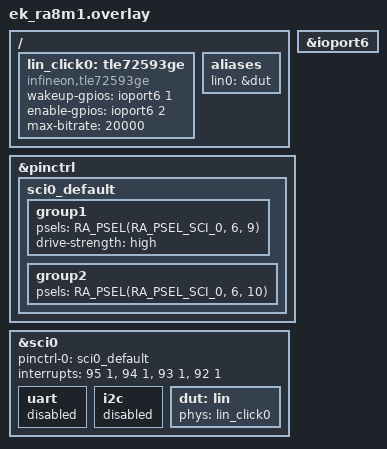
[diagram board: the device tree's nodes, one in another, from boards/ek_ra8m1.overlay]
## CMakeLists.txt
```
# SPDX-License-Identifier: Apache-2.0

cmake_minimum_required(VERSION 3.20.0)
find_package(Zephyr REQUIRED HINTS $ENV{ZEPHYR_BASE})
project(lin_ncv7430)

file(GLOB app_sources src/*.c)
target_sources(app PRIVATE ${app_sources})
```

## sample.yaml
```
sample:
  name: LIN driver NCV7430 sample
tests:
  sample.drivers.lin.ncv7430:
    tags: lin
    depends_on: lin
    integration_platforms:
      - ek_ra8m1/r7fa8m1ahecbd
    harness: console
    harness_config:
      type: one_line
      regex:
        - "NCV7430 sample started"
    extra_args:
      - platform:ek_ra8m1/r7fa8m1ahecbd:SHIELD=mikroe_lin_click
```

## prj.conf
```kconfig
CONFIG_LIN=y
```

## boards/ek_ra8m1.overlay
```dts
/*
 * Copyright (c) 2025 Renesas Electronics Corporation
 *
 * SPDX-License-Identifier: Apache-2.0
 */

/ {
	lin_click0: tle72593ge {
		compatible = "infineon,tle72593ge", "lin-transceiver-gpio";
		wakeup-gpios = <&ioport6 1 GPIO_ACTIVE_HIGH>;
		enable-gpios = <&ioport6 2 GPIO_ACTIVE_HIGH>;
		max-bitrate = <20000>;
		#phy-cells = <0>;
	};

	aliases {
		lin0 = &dut;
	};
};

&ioport6 {
	status = "okay";
};

&pinctrl {
	sci0_default: sci0_default {
		group1 {
			/* TXD */
			psels = <RA_PSEL(RA_PSEL_SCI_0, 6, 9)>;
			drive-strength = "high";
		};

		group2 {
			/* RXD */
			psels = <RA_PSEL(RA_PSEL_SCI_0, 6, 10)>;
		};
	};
};

&sci0 {
	pinctrl-0 = <&sci0_default>;
	pinctrl-names = "default";
	interrupts = <95 1>, <94 1>, <93 1>, <92 1>;
	interrupt-names = "rxi", "txi", "tei", "eri";
	status = "okay";

	uart {
		status = "disabled";
	};

	i2c {
		status = "disabled";
	};

	dut: lin {
		phys = <&lin_click0>;
		status = "okay";
	};
};
```

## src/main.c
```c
/*
 * Copyright (c) 2025 Renesas Electronics Corporation
 *
 * SPDX-License-Identifier: Apache-2.0
 */

#include <zephyr/kernel.h>
#include <zephyr/sys/printk.h>
#include <zephyr/device.h>
#include <zephyr/drivers/lin.h>
#include <zephyr/sys/byteorder.h>

#include "ncv7430.h"

#define LIN_BUS_BAUDRATE            19200U
#define LIN_BUS_BREAK_LEN           13U
#define LIN_BUS_BREAK_DELIMITER_LEN 1U

#define LED_CHANGE_INTERVAL_MS 1000

/* RGB LED test sequence (RGB888 format, separate channels) */
static const struct rgb_led_color rgb_led_test_colors[8] = {
	{255, 0, 0},   {0, 255, 0},   {0, 0, 255},     {255, 255, 0},
	{0, 255, 255}, {255, 0, 255}, {255, 255, 255}, {0, 0, 0},
};

/* RGB LED color names in string */
static const unsigned char rgb_test_color_name[][8] = {
	"Red", "Green", "Blue", "Yellow", "Cyan", "Magenta", "White", "Black",
};

static const struct lin_config dut_config = {
	.mode = LIN_MODE_COMMANDER,
	.baudrate = LIN_BUS_BAUDRATE,
	.break_len = LIN_BUS_BREAK_LEN,
	.break_delimiter_len = LIN_BUS_BREAK_DELIMITER_LEN,
	.flags = 0,
};

static unsigned int current_led_idx;

#if DT_HAS_ALIAS(lin0)
static const struct device *const dev = DEVICE_DT_GET(DT_ALIAS(lin0));
#else
#error "No LIN device found."
#endif

int main(void)
{
	int ret;

	ret = device_is_ready(dev);
	if (!ret) {
		printk("NCV7430 device not found\n");
		return 0;
	}

	ret = lin_configure(dev, &dut_config);
	if (ret) {
		printk("LIN configure failed: %d\n", ret);
		return 0;
	}

	ret = lin_start(dev);
	if (ret) {
		printk("LIN start failed: %d\n", ret);
		return 0;
	}

	ret = ncv7430_init(dev, NCV7430_NODE_ADDRESS);
	if (ret) {
		printk("NCV7430 initialization failed: %d\n", ret);
		return 0;
	}

	printk("NCV7430 sample started\n");
	current_led_idx = 0;

	while (true) {
		struct rgb_led_color color = rgb_led_test_colors[current_led_idx];
		struct rgb_led_color read_color;
		uint32_t color_code;

		ret = ncv7430_set_led_color(dev, NCV7430_NODE_ADDRESS, &color);
		if (ret != 0) {
			printk("Failed to set LED color: %d\n", ret);
			return 0;
		}

		ret = ncv7430_get_led_color(dev, NCV7430_NODE_ADDRESS, &read_color);
		if (ret != 0) {
			printk("Failed to get LED color: %d\n", ret);
			return 0;
		}

		color_code = sys_get_be24((uint8_t *)&read_color);
		printk("Set LED color: %s - read back actual color code: 0x%06X\n",
		       rgb_test_color_name[current_led_idx], color_code);

		if ((read_color.red != color.red) || (read_color.green != color.green) ||
		    (read_color.blue != color.blue)) {
			printk("Warning: Mismatch in set and read back color "
			       "values!\n");
		}

		current_led_idx++;
		if (current_led_idx == ARRAY_SIZE(rgb_led_test_colors)) {
			current_led_idx = 0;
		}

		k_msleep(LED_CHANGE_INTERVAL_MS);
	}

	return 0;
}
```

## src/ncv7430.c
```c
/*
 * Copyright (c) 2025 Renesas Electronics Corporation
 *
 * SPDX-License-Identifier: Apache-2.0
 */

#include <string.h>

#include <zephyr/kernel.h>
#include <zephyr/sys/printk.h>
#include <zephyr/drivers/lin.h>

#include "ncv7430.h"

static struct lin_msg ncv7430_msg;
static uint8_t tx_data[LIN_MAX_DLEN];
static uint8_t rx_data[LIN_MAX_DLEN];
static volatile bool tx_complete;
static volatile bool rx_complete;
static volatile uint32_t ncv7430_event_flags;

void ncv7430_event_handler(const struct device *dev, const struct lin_event *event, void *user_data)
{
	ARG_UNUSED(dev);
	ARG_UNUSED(user_data);

	switch (event->type) {
	case LIN_EVT_TX_DATA:
		tx_complete = true;
		ncv7430_event_flags = event->status;
		break;
	case LIN_EVT_RX_DATA:
		rx_complete = true;
		ncv7430_event_flags = event->status;
		break;
	case LIN_EVT_ERR:
		printk("NCV7430 LIN error event: 0x%08X\n", event->error_flags);
		ncv7430_event_flags = -EIO;
		break;
	default:
		break;
	}
}

static int ncv7430_send_command(const struct device *dev, const uint8_t cmd_id, const uint8_t *data,
				const uint8_t data_len)
{
	int ret;

	tx_complete = false;
	ncv7430_event_flags = 0;

	ncv7430_msg.id = cmd_id;
	ncv7430_msg.data_len = data_len;
	ncv7430_msg.checksum_type = LIN_CHECKSUM_CLASSIC;
	ncv7430_msg.flags = 0;

	memcpy(ncv7430_msg.data, data, data_len);

	ret = lin_send(dev, &ncv7430_msg, K_FOREVER);
	if (ret) {
		printk("Failed to send NCV7430 command 0x%02X: %d\n", cmd_id, ret);
		return ret;
	}

	if (!WAIT_FOR(tx_complete, 500000, k_sleep(K_MSEC(10)))) {
		printk("Timeout waiting for NCV7430 command 0x%02X TX complete\n", cmd_id);
		return -EAGAIN;
	}

	return ncv7430_event_flags;
}

static int ncv7430_request_response(const struct device *dev, const uint8_t cmd_id, uint8_t *data,
				    const uint8_t data_len)
{
	int ret;

	rx_complete = false;
	ncv7430_event_flags = 0;

	ncv7430_msg.id = cmd_id;
	ncv7430_msg.data_len = data_len;
	ncv7430_msg.checksum_type = LIN_CHECKSUM_CLASSIC;
	ncv7430_msg.flags = 0;

	ret = lin_receive(dev, &ncv7430_msg, K_FOREVER);
	if (ret) {
		printk("Failed to receive NCV7430 response for command 0x%02X: %d\n", cmd_id, ret);
		return ret;
	}

	if (!WAIT_FOR(rx_complete, 500000, k_sleep(K_MSEC(10)))) {
		printk("Timeout waiting for NCV7430 response for command 0x%02X\n", cmd_id);
		return -EAGAIN;
	}

	memcpy(data, ncv7430_msg.data, data_len);

	return ncv7430_event_flags;
}

int ncv7430_init(const struct device *dev, uint8_t addr)
{
	uint8_t leds_en = (NCV7430_LED_R_EN_MSK | NCV7430_LED_G_EN_MSK | NCV7430_LED_B_EN_MSK);
	int ret;

	ret = lin_set_event_callback(dev, ncv7430_event_handler, NULL);
	if (ret) {
		printk("Failed to set NCV7430 event handler: %d\n", ret);
		return ret;
	}

	/*
	 * NCV7430 Set_LED_Control WRITING FRAME
	 * Frame ID: 0x23
	 * Data Length: 4 bytes
	 * Data:
	 *      Byte 0:
	 *              [7:7] Broad: Individual Addressing (1) or Group Addressing (0)
	 *              [6:6] Fixed as 1
	 *              [5:0] AD: NCV7430 Node Address - unused in case of Group Addressing
	 *              Other bits are filled as 0
	 *      Byte 1: 0xFF (FILL)
	 *      Byte 2: 0xFF (FILL)
	 *      Byte 3:
	 *              [0:0] Fixed as 1
	 *              [3:1] LEDs Enable: 0x07 (All LEDs On), 0x00 (All LEDs Off)
	 *              [5:5] Global LEDs Enable: 1 (Enabled), 0 (Disabled)
	 *              [6:6] LED Modulation Frequency: 0 (122 Hz), 1 (244 Hz)
	 *              Other bits are filled as 0
	 */
	tx_data[0] = (addr & 0x3F) | BIT(6) | BIT(7);
	tx_data[1] = NCV7430_FILL;
	tx_data[2] = NCV7430_FILL;
	tx_data[3] = BIT(0) | (leds_en << 1) | BIT(5) | NCV7430_LED_MOD_FREQ_122_HZ << 6;

	ret = ncv7430_send_command(dev, NCV7430_FRAME_ID_SET_LED_CONTROL_WRITING, tx_data,
				   NCV7430_4_BYTES);
	if (ret) {
		return ret;
	}

	return 0;
}

int ncv7430_set_led_color(const struct device *dev, uint8_t addr, struct rgb_led_color *color)
{
	/**
	 * NCV7430 Set_Color WRITING FRAME
	 * Frame ID: 0x24
	 * Data Length: 8 bytes
	 * Data:
	 *      Byte 0:
	 *              [7:7] Broad: Individual Addressing (1) or Group Addressing (0)
	 *              [6:6] Fixed as 1
	 *              [5:0] AD: NCV7430 Node Address - unused in case of Group Addressing
	 *              Other bits are filled as 0
	 *      Byte 1: 0xFF (FILL)
	 *      Byte 2: 0xFF (FILL)
	 *      Byte 3: Fading time - set as 0 for immediate change
	 *      Byte 4:
	 *              [3:0] Intensity: 0x00 (Min) to 0xF (Max)
	 *              [4:4] Fixed as 1
	 *              [5:5] LEDs on/off: 1 (On), 0 (Off)
	 *              Other bits are filled as 0
	 *      Byte 5: Red Color Value: 0x00 (Min) to 0xFF (Max)
	 *      Byte 6: Green Color Value: 0x00 (Min) to 0xFF (Max)
	 *      Byte 7: Blue Color Value: 0x00 (Min) to 0xFF (Max)
	 */
	tx_data[0] = (addr & 0x3F) | BIT(6) | BIT(7);
	tx_data[1] = NCV7430_FILL;
	tx_data[2] = NCV7430_FILL;
	tx_data[3] = 0x00; /* Fading time == 0 */
	tx_data[4] = 0x01 | BIT(4) | BIT(5);
	tx_data[5] = color->green;
	tx_data[6] = color->red;
	tx_data[7] = color->blue;

	return ncv7430_send_command(dev, NCV7430_FRAME_ID_SET_LED_COLOR_WRITING, tx_data,
				    NCV7430_8_BYTES);
}

int ncv7430_get_led_color(const struct device *dev, uint8_t addr, struct rgb_led_color *color)
{
	int ret;

	/**
	 * NCV7430 Get_Actual_Param1 WRITING FRAME
	 * First send the command to read the full set of the actual parameters of the NCV7430
	 * Frame ID: 0x3c
	 * Data Length: 8 bytes
	 * Data:
	 *      Byte 0:
	 *              [7:7] Broad: Individual Addressing (1) or Group
	 *              [6:6] Fixed as 1
	 *              [5:0] AD: NCV7430 Node Address - unused in case of Group Addressing
	 *              Other bits are filled as 0
	 *      Byte 1: 0xFF (FILL)
	 */
	tx_data[0] = NCV7430_APPCMD;
	tx_data[1] = NCV7430_CMD_GET_ACTUAL_PARAM_1 | BIT(7);
	tx_data[2] = (addr & 0x3F) | BIT(6) | BIT(7);
	tx_data[3] = NCV7430_FILL;
	tx_data[4] = NCV7430_FILL;
	tx_data[5] = NCV7430_FILL;
	tx_data[6] = NCV7430_FILL;
	tx_data[7] = NCV7430_FILL;

	ret = ncv7430_send_command(dev, NCV7430_COMMANDER_COMMAND, tx_data, NCV7430_8_BYTES);
	if (ret) {
		return ret;
	}

	/**
	 * NCV7430 Get_Actual_Param In frame response 1
	 * Frame ID: 0x3D
	 * Data Length: 8 bytes
	 * Data:
	 *      Byte 0:
	 *              [7:7] Broad: Individual Addressing (1) or Group Addressing (0)
	 *              [6:6] Fixed as 1
	 *              [5:0] AD: NCV7430 Node Address - unused in case of Group Addressing
	 *      Byte 1: Green Color Value: 0x00 (Min) to 0xFF (Max)
	 *      Byte 2: Red Color Value: 0x00 (Min) to 0xFF (Max)
	 *      Byte 3: Blue Color Value: 0x00 (Min) to 0xFF (Max)
	 *      Byte 4: 0xFF (FILL)
	 *      Byte 5: 0xFF (FILL)
	 *      Byte 6: 0xFF (FILL)
	 *      Byte 7: 0xFF (FILL)
	 */
	ret = ncv7430_request_response(dev, NCV7430_RESPONDER_RESPONSE, rx_data, NCV7430_8_BYTES);
	if (ret) {
		return ret;
	}

	color->red = rx_data[2];
	color->green = rx_data[1];
	color->blue = rx_data[3];

	return 0;
}
```

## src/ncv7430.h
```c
/*
 * Copyright (c) 2025 Renesas Electronics Corporation
 *
 * SPDX-License-Identifier: Apache-2.0
 */

#ifndef NCV7430_H_
#define NCV7430_H_

#include <stdint.h>

#include <zephyr/device.h>
#include <zephyr/sys/util.h>

/* NCV7430 command definitions for commander command frames */
#define NCV7430_CMD_GET_FULL_STATUS    0x01
#define NCV7430_CMD_GET_ACTUAL_PARAM_1 0x02
#define NCV7430_CMD_GET_ACTUAL_PARAM_2 0x03
#define NCV7430_CMD_GET_OTP_PARAM_1    0x04
#define NCV7430_CMD_GET_OTP_PARAM_2    0x05

/* NCV7430 supported response frame identifiers */
#define NCV7430_FRAME_ID_GET_LED_CONTROL_RESPONSE 0x10
#define NCV7430_FRAME_ID_GET_STATUS_RESPONSE      0x11
#define NCV7430_FRAME_ID_GET_COLOR_RESPONSE       0x12

/* NCV7430 supported reading frame identifiers */
#define NCV7430_FRAME_ID_READING 0x20

/* NCV7430 supported writing frame identifiers */
#define NCV7430_FRAME_ID_SET_LED_CONTROL_WRITING         0x23
#define NCV7430_FRAME_ID_SET_LED_COLOR_WRITING           0x24
#define NCV7430_FRAME_ID_SET_PRIMARY_CAL_PARAM_WRITING   0x25
#define NCV7430_FRAME_ID_SET_OTP_PARAM_WRITING           0x27
#define NCV7430_FRAME_ID_SET_INTENSITY_SHORT_WRITING     0x2E
#define NCV7430_FRAME_ID_SET_COLOR_SHORT_WRITING         0x2F
#define NCV7430_FRAME_ID_SET_SECONDARY_CAL_PARAM_WRITING 0x36

/* Standard LIN frame identifiers */
#define NCV7430_COMMANDER_COMMAND  0x3C
#define NCV7430_RESPONDER_RESPONSE 0x3D

/* NCV7430 data lengths */
#define NCV7430_8_BYTES 8
#define NCV7430_4_BYTES 4
#define NCV7430_2_BYTES 2

/* NCV7430 broad bit values */
#define NCV7430_GROUP_ADDRESSING      0
#define NCV7430_INDIVIDUAL_ADDRESSING 1

/* AppCMD value is always 0x80 */
#define NCV7430_APPCMD 0x80

/* For filling unused payload bytes. Unused bytes must be set as 1 for NCV7430 */
#define NCV7430_FILL 0xff

/* Mask helpers */
#define NCV7430_6_BITS_MASK   0x3F
#define NCV7430_AD_MASK       0xC0
#define NCV7430_BIT_7_MASK    0x80
#define NCV7430_BIT_6_MASK    0x40
#define NCV7430_BITS_1_3_MASK 0x0E
#define NCV7430_BITS_0_3_MASK BIT_MASK(4)
#define NCV7430_BITS_0_5_MASK BIT_MASK(6)

/* NCV7430 LIN node address */
#define NCV7430_NODE_ADDRESS 0x00

/* NCV7430 LED enable mask definitions */
#define NCV7430_LED_R_EN_MSK BIT(0)
#define NCV7430_LED_G_EN_MSK BIT(1)
#define NCV7430_LED_B_EN_MSK BIT(2)

/* NCV7430 LED modulation frequency definitions */
#define NCV7430_LED_MOD_FREQ_122_HZ 0
#define NCV7430_LED_MOD_FREQ_244_HZ 1

/* RGB LED color structure */
struct rgb_led_color {
	uint8_t red;
	uint8_t green;
	uint8_t blue;
};

/* NCV7430 API function prototypes */
int ncv7430_init(const struct device *dev, uint8_t addr);
int ncv7430_set_led_color(const struct device *dev, uint8_t addr, struct rgb_led_color *color);
int ncv7430_get_led_color(const struct device *dev, uint8_t addr, struct rgb_led_color *color);

#endif /* NCV7430_H_ */
```
